# SGX_PRM register map
Vendor: Texas Instruments
Peripheral module from a debugger description file (folder omap36xx).
Registers are 32-bit, access per field, reset 0x1 unless marked. A register's access mark holds for its fields unless they carry their own. Offsets are as the file gives them; lines under a group give offsets from that group; [hi:lo] are bit positions; {n}, {i} and the like mark numbered series; 'fields as' and 'values as' point back to an identical list; <NAME> marks a mode.

## SGX_PRM
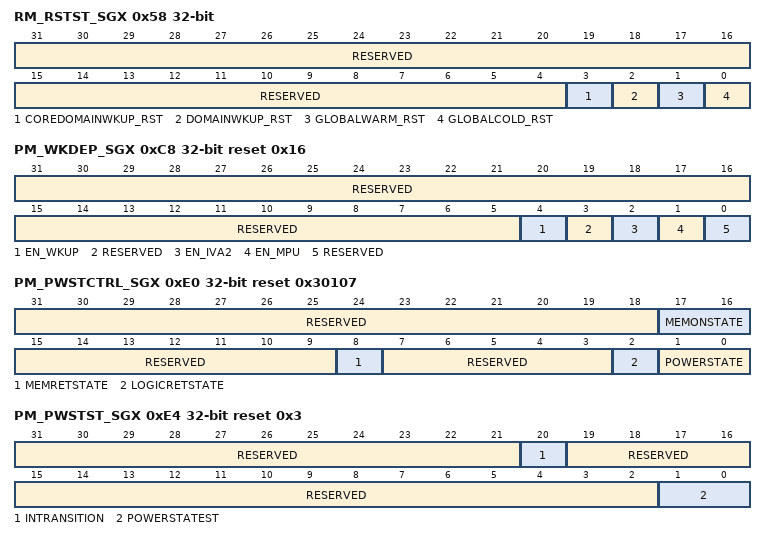
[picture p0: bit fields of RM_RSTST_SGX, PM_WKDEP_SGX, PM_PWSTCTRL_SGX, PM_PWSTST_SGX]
0x58 RM_RSTST_SGX — This register logs the different reset sources of the SGX domain. Each bit is set upon release of the domain reset signal. Must be cleared by software.
  [31:4] RESERVED ro — Write 0s for future compatibility. Read returns 0.
  [3] COREDOMAINWKUP_RST rw — CORE domain wake-up reset
    0=COREDOMAINWKUP_RST_0_r (No power domain wake-up reset.); 0=COREDOMAINWKUP_RST_0_w (Status bit unchanged); 1=COREDOMAINWKUP_RST_1_r (SGX domain has been reset following a CORE power domain wake-up from OFF to ON.); 1=COREDOMAINWKUP_RST_1_w (Status bit is cleared to 0.)
  [2] DOMAINWKUP_RST rw — Power domain wake-up reset
    0=DOMAINWKUP_RST_0_r (SGX domain is not reset); 0=DOMAINWKUP_RST_0_w (Status bit unchanged); 1=DOMAINWKUP_RST_1_r (SGX domain has been reset following a SGX domain wake-up.); 1=DOMAINWKUP_RST_1_w (Status bit is cleared to 0.)
  [1] GLOBALWARM_RST rw — Global warm reset
    0=GLOBALWARM_RST_0_r (No global warm reset.); 0=GLOBALWARM_RST_0_w (Status bit unchanged); 1=GLOBALWARM_RST_1_r (SGX domain has been reset upon a global warm reset); 1=GLOBALWARM_RST_1_w (Status bit is cleared to 0.)
  [0] GLOBALCOLD_RST rw — Global cold reset
    0=GLOBALCOLD_RST_0_r (No global cold reset.); 0=GLOBALCOLD_RST_0_w (Status bit unchanged); 1=GLOBALCOLD_RST_1_r (SGX domain has been reset upon a global cold reset); 1=GLOBALCOLD_RST_1_w (Status bit is cleared to 0.)
0xC8 PM_WKDEP_SGX reset 0x16 — This register allows enabling or disabling the wake-up of the SGX domain upon another domain wakeup.
  [31:5] RESERVED ro — Write 0s for future compatibility. Read returns 0.
  [4] EN_WKUP rw — WAKEUP domain dependency
    0=SGX domain is independent of WKUP domain wake-up event; 1=SGX domain is woken-up upon WKUP domain wake-up event
  [3] RESERVED ro — Write 0s for future compatibility. Read returns 0.
  [2] EN_IVA2 rw — IVA2 domain dependency
    0=SGX domain is independent of IVA2 domain wake-up event; 1=SGX domain is woken-up upon IVA2 domain wake-up event
  [1] EN_MPU rw — MPU domain dependency
    0=SGX domain is independent of MPU domain wake-up; 1=SGX domain is woken-up upon MPU domain wake-up
  [0] RESERVED ro — Write 0s for future compatibility. Read returns 0.
0xE0 PM_PWSTCTRL_SGX reset 0x30107 — This register controls the SGX domain power state transition.
  [31:18] RESERVED ro — Write 0s for future compatibility. Read returns 0.
  [17:16] MEMONSTATE ro — Memory state when ON
    3=Memory is always ON when domain is ON
  [15:9] RESERVED ro — Write 0s for future compatibility. Read returns 0.
  [8] MEMRETSTATE ro — Memory state when RETENTION
    1=Memory is always retained when domain is in RETENTION state
  [7:3] RESERVED ro — Write 0s for future compatibility. Read returns 0.
  [2] LOGICRETSTATE ro — Logic state when RETENTION
    1=Logic is always retained when domain is in RETENTION state
  [1:0] POWERSTATE rw — Power state control
    0=OFF state; 1=RETENTION state; 3=ON state
0xE4 PM_PWSTST_SGX ro reset 0x3 — This register provides a status on the power state transition of the SGX domain.
  [31:21] RESERVED — Read returns 0.
  [20] INTRANSITION — Domain transition status
    0=No transition; 1=SGX power domain transition is in progress
  [19:2] RESERVED — Read returns 0.
  [1:0] POWERSTATEST — Current power state status
    0=Power domain is OFF; 1=Power domain is in RETENTION; 2=Power domain is INACTIVE; 3=Power domain is ON
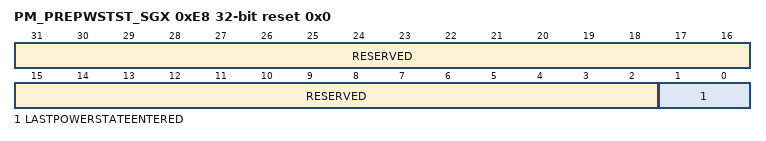
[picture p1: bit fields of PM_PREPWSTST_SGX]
0xE8 PM_PREPWSTST_SGX reset 0x0 — This register provides a status on the SGX domain previous power state. It indicates the state entered during the last sleep transition.
  [31:2] RESERVED ro — Write 0s for future compatibility. Read returns 0.
  [1:0] LASTPOWERSTATEENTERED rw
    0=SGX domain was previously OFF; 1=SGX domain was previously in RETENTION; 2=SGX domain was previously INACTIVE; 3=SGX domain was previously ON
